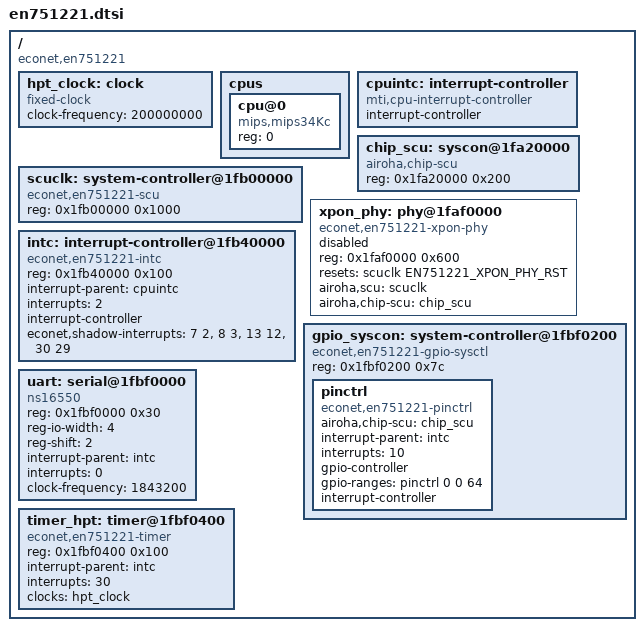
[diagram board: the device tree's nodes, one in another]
// SPDX-License-Identifier: (GPL-2.0-only OR BSD-2-Clause)
/dts-v1/;

#include <dt-bindings/reset/econet,en751221-scu.h>

/ {
	compatible = "econet,en751221";
	#address-cells = <1>;
	#size-cells = <1>;

	hpt_clock: clock {
		compatible = "fixed-clock";
		#clock-cells = <0>;
		clock-frequency = <200000000>;  /* 200 MHz */
	};

	cpus: cpus {
		#address-cells = <1>;
		#size-cells = <0>;

		cpu@0 {
			device_type = "cpu";
			compatible = "mips,mips34Kc";
			reg = <0>;
		};
	};

	cpuintc: interrupt-controller {
		compatible = "mti,cpu-interrupt-controller";
		interrupt-controller;
		#address-cells = <0>;
		#interrupt-cells = <1>;
	};

	chip_scu: syscon@1fa20000 {
		compatible = "airoha,chip-scu", "syscon";
		reg = <0x1fa20000 0x200>;
	};

	scuclk: system-controller@1fb00000 {
		compatible = "econet,en751221-scu", "syscon";
		reg = <0x1fb00000 0x1000>;

		#clock-cells = <1>;
		#reset-cells = <1>;
	};

	xpon_phy: phy@1faf0000 {
		compatible = "econet,en751221-xpon-phy";
		reg = <0x1faf0000 0x600>;

		resets = <&scuclk EN751221_XPON_PHY_RST>;
		reset-names = "phy";

		airoha,scu = <&scuclk>;
		airoha,chip-scu = <&chip_scu>;

		#phy-cells = <0>;
		status = "disabled";
	};

	intc: interrupt-controller@1fb40000 {
		compatible = "econet,en751221-intc";
		reg = <0x1fb40000 0x100>;
		interrupt-parent = <&cpuintc>;
		interrupts = <2>;

		interrupt-controller;
		#interrupt-cells = <1>;
		econet,shadow-interrupts = <7 2>, <8 3>, <13 12>, <30 29>;
	};

	gpio_syscon: system-controller@1fbf0200 {
		compatible = "econet,en751221-gpio-sysctl", "syscon",
			     "simple-mfd";
		reg = <0x1fbf0200 0x7c>;

		pinctrl: pinctrl {
			compatible = "econet,en751221-pinctrl";
			airoha,chip-scu = <&chip_scu>;

			interrupt-parent = <&intc>;
			interrupts = <10>;

			gpio-controller;
			#gpio-cells = <2>;
			gpio-ranges = <&pinctrl 0 0 64>;

			interrupt-controller;
			#interrupt-cells = <2>;
		};
	};

	uart: serial@1fbf0000 {
		compatible = "ns16550";
		reg = <0x1fbf0000 0x30>;
		reg-io-width = <4>;
		reg-shift = <2>;
		interrupt-parent = <&intc>;
		interrupts = <0>;
		/*
		 * Conversion of baud rate to clock frequency requires a
		 * computation that is not in the ns16550 driver, so this
		 * uart is fixed at 115200 baud.
		 */
		clock-frequency = <1843200>;
	};

	timer_hpt: timer@1fbf0400 {
		compatible = "econet,en751221-timer";
		reg = <0x1fbf0400 0x100>;

		interrupt-parent = <&intc>;
		interrupts = <30>;
		clocks = <&hpt_clock>;
	};
};
